AUTOSAR XML (schema 4-3-1)
package /TPC_Composition/Components
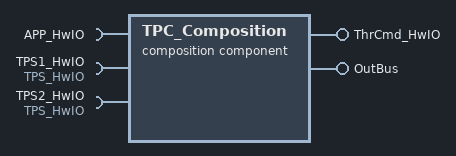
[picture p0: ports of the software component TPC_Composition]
  composition sw component type TPC_Composition
    require port APP_HwIO: required-interface=APP_HwIO
    require port TPS1_HwIO: required-interface=TPS_HwIO
    require port TPS2_HwIO: required-interface=TPS_HwIO
    provide port ThrCmd_HwIO: provided-interface=ThrCmd_HwIO
    provide port OutBus: provided-interface=OutBus
    7 x component:
      Ctrl: type=Controller
      Actuator: type=Actuator
      Ctrl2: type=ctrl2
      TPS_Primary: type=ThrottleSensor1
      TPS_Secondary: type=ThrottleSensor2
      Monitor: type=ThrottleSensorMonitor
      PedalSensor: type=PedalSensor
    connect Ctrl.ThrCmd_Percent -> Actuator.ThrCmd_Percent
    delegate Actuator.ThrCmd_HwIO <-> outer port ThrCmd_HwIO
    delegate Ctrl2.OutBus <-> outer port OutBus
    connect TPS_Primary.TPS_Primary -> Monitor.TPS_Primary
    connect TPS_Secondary.TPS_Secondary -> Monitor.TPS_Secondary
    connect Monitor.TPS_Percent -> Ctrl.TPS_Percent
    connect Monitor.TPS_Percent -> Ctrl2.InBus2
    connect PedalSensor.APP_Percent -> Ctrl.APP_Percent
    connect PedalSensor.APP_Percent -> Ctrl2.InBus1
    delegate TPS_Primary.TPS_HwIO <-> outer port TPS1_HwIO
    delegate TPS_Secondary.TPS_HwIO <-> outer port TPS2_HwIO
    delegate PedalSensor.APP_HwIO <-> outer port APP_HwIO
